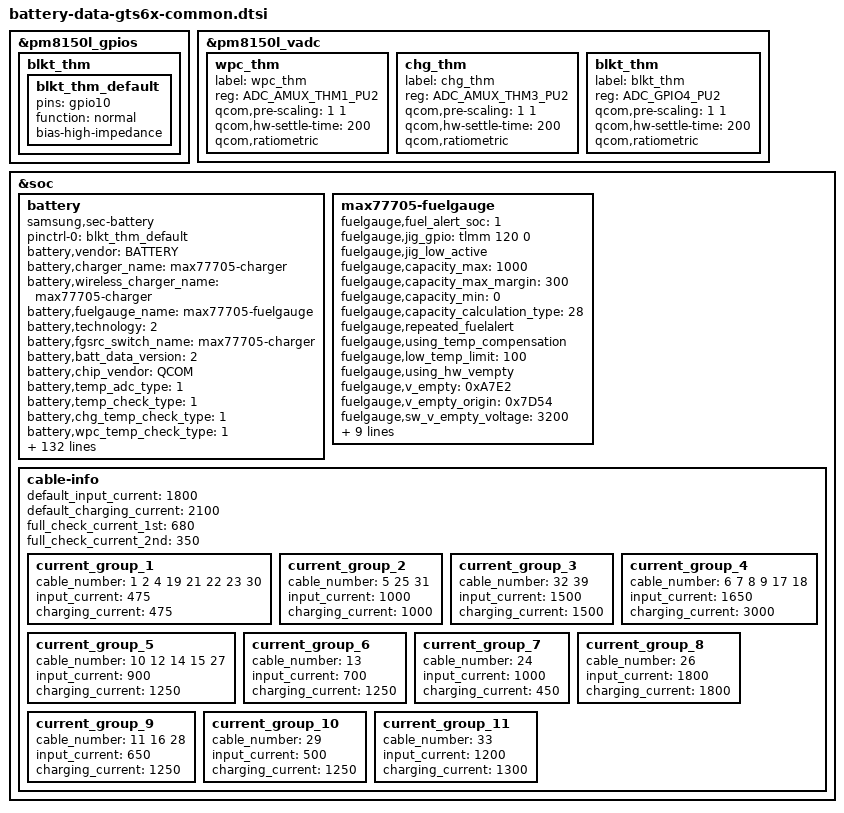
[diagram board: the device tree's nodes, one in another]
/* Copyright (c) 2014, The Linux Foundation. All rights reserved.
 *
 * This program is free software; you can redistribute it and/or modify
 * it under the terms of the GNU General Public License version 2 and
 * only version 2 as published by the Free Software Foundation.
 *
 * This program is distributed in the hope that it will be useful,
 * but WITHOUT ANY WARRANTY; without even the implied warranty of
 * MERCHANTABILITY or FITNESS FOR A PARTICULAR PURPOSE.  See the
 * GNU General Public License for more details.
 */

&pm8150l_gpios {
	blkt_thm { /* GPIO_10 */
		blkt_thm_default: blkt_thm_default {
			pins = "gpio10";
			function = "normal";
			bias-high-impedance;
		};
	};
};

&pm8150l_vadc {
	wpc_thm { /* AMUX_1 */
		label = "wpc_thm";
		reg = <ADC_AMUX_THM1_PU2>;
		qcom,pre-scaling = <1 1>;
		qcom,hw-settle-time = <200>;
		qcom,ratiometric;
	};
	chg_thm { /* AMUX_3 */
		label = "chg_thm";
		reg = <ADC_AMUX_THM3_PU2>;
		qcom,pre-scaling = <1 1>;
		qcom,hw-settle-time = <200>;
		qcom,ratiometric;
	};
	blkt_thm { /* GPIO_10 */
		label = "blkt_thm";
		reg = <ADC_GPIO4_PU2>;
		qcom,pre-scaling = <1 1>;
		qcom,hw-settle-time = <200>;
		qcom,ratiometric;
	};
};

&soc {
	battery {
		status = "okay";
		compatible = "samsung,sec-battery";
		pinctrl-names = "default";
		pinctrl-0 = <&blkt_thm_default>;
		battery,vendor = "BATTERY";
		battery,charger_name = "max77705-charger";
		battery,wireless_charger_name = "max77705-charger";
		battery,fuelgauge_name = "max77705-fuelgauge";
		battery,technology = <2>; /* POWER_SUPPLY_TECHNOLOGY_LION */
		battery,fgsrc_switch_name = "max77705-charger"; /* Fuelgauge voltage source */

		battery,batt_data_version = <2>;

		battery,chip_vendor = "QCOM";
		battery,temp_adc_type = <1>; /* SEC_BATTERY_ADC_TYPE_AP */

		battery,temp_check_type = <1>; /* SEC_BATTERY_TEMP_CHECK_ADC */
		battery,chg_temp_check_type = <1>;
		battery,wpc_temp_check_type = <1>;  // 0 /* SEC_BATTERY_TEMP_CHECK_NONE */
		battery,blkt_temp_check_type = <1>;

		battery,thermal_source = <2>; /* SEC_BATTERY_THERMAL_SOURCE_ADC */
		battery,chg_thermal_source = <2>; /* SEC_BATTERY_THERMAL_SOURCE_ADC */
		battery,wpc_thermal_source = <2>; /* SEC_BATTERY_THERMAL_SOURCE_ADC */
		battery,blkt_thermal_source = <2>; /* SEC_BATTERY_THERMAL_SOURCE_ADC */

		battery,polling_time = <10 30 30 30 3600>;

		battery,temp_table_adc = <123657 151426 179195 211497 245407
						288105 326527 385524 450849 530953
						616406 708974 815008 922577 1031321
						1142913 1245969 1348146 1442228 1527594
						1602039 1667278 1716298>;
		battery,temp_table_data = <900 850 800 750 700
						650 600 550 500 450
						400 350 300 250 200
						150 100 50 0 (-50)
						(-100) (-150) (-200)>;

		battery,chg_temp_table_adc = <130989 157146 183303 215909 251412
						293432 331090 389582 455420 534760
						620695 712780 818114 924062 1032453
						1143316 1248384 1350302 1442444 1526988
						1601267 1666082 1715606>;
		battery,chg_temp_table_data = <900 850 800 750 700
						650 600 550 500 450
						400 350 300 250 200
						150 100 50 0 (-50)
						(-100) (-150) (-200)>;

		battery,wpc_temp_table_adc = <123657 151426 179195 211497 245407
						288105 326527 385524 450849 530953
						616406 708974 815008 922577 1031321
						1142913 1245969 1348146 1442228 1527594
						1602039 1667278 1716298>;
		battery,wpc_temp_table_data = <900 850 800 750 700
						650 600 550 500 450
						400 350 300 250 200
						150 100 50 0 (-50)
						(-100) (-150) (-200)>;

		battery,blkt_temp_table_adc = <128134 154443 180752 213105 248464
						290073 328113 386677 452529 532028
						618381 711050 817149 923853 1033044
						1144355 1250518 1352292 1444679 1529692
						1603762 1668230 1717624>;
		battery,blkt_temp_table_data = <900 850 800 750 700
						650 600 550 500 450
						400 350 300 250 200
						150 100 50 0 (-50)
						(-100) (-150) (-200)>;

		battery,adc_check_count = <5>;

		battery,cable_check_type = <4>; /* SEC_BATTERY_CABLE_CHECK_PSY */
		battery,cable_source_type = <1>; /* SEC_BATTERY_CABLE_SOURCE_EXTERNAL */
		battery,polling_type = <1>; /* SEC_BATTERY_MONITOR_ALARM */
		battery,monitor_initial_count = <0>;

		battery,battery_check_type = <0>; /* SEC_BATTERY_CHECK_NONE */
		battery,check_count = <0>;
		battery,check_adc_max = <1440>;
		battery,check_adc_min = <0>;

		battery,ovp_uvlo_check_type = <3>; /* SEC_BATTERY_OVP_UVLO_CHGPOLLING */

		battery,temp_check_count = <1>;
		battery,temp_highlimit_threshold_event = <800>;
		battery,temp_highlimit_recovery_event = <780>;
		battery,temp_high_threshold_event = <500>;
		battery,temp_high_recovery_event = <450>;
		battery,temp_low_threshold_event = <0>;
		battery,temp_low_recovery_event = <50>;
		battery,temp_highlimit_threshold_normal = <800>;
		battery,temp_highlimit_recovery_normal = <780>;
		battery,temp_high_threshold_normal = <500>;
		battery,temp_high_recovery_normal = <450>;
		battery,temp_low_threshold_normal = <0>;
		battery,temp_low_recovery_normal = <50>;
		battery,temp_highlimit_threshold_lpm = <800>;
		battery,temp_highlimit_recovery_lpm = <780>;
		battery,temp_high_threshold_lpm = <500>;
		battery,temp_high_recovery_lpm = <450>;
		battery,temp_low_threshold_lpm = <0>;
		battery,temp_low_recovery_lpm = <50>;
		battery,full_check_type = <2>; /* SEC_BATTERY_FULLCHARGED_FG_CURRENT */
		battery,full_check_type_2nd = <2>; /* SEC_BATTERY_FULLCHARGED_FG_CURRENT */
		battery,full_check_count = <1>;
		battery,chg_gpio_full_check = <0>;
		battery,chg_polarity_full_check = <1>;

		battery,chg_high_temp = <800>;
		battery,chg_high_temp_recovery = <770>;
		battery,chg_input_limit_current = <1000>;
		battery,chg_charging_limit_current = <1500>;

		battery,store_mode_afc_input_current = <700>;

		battery,sleep_mode_limit_current = <500>;

		battery,mix_high_temp = <410>;
		battery,mix_high_chg_temp = <595>;
		battery,mix_high_temp_recovery = <380>;

		/* SEC_BATTERY_FULL_CONDITION_NOTIMEFULL | SEC_BATTERY_FULL_CONDITION_VCELL */
		battery,full_condition_type = <9>;
		battery,full_condition_soc = <93>;
		battery,full_condition_vcell = <4250>;

		battery,recharge_check_count = <1>;
		battery,recharge_condition_type = <4>; /* SEC_BATTERY_RECHARGE_CONDITION_VCELL */
		battery,recharge_condition_soc = <98>;
		battery,recharge_condition_vcell = <4280>;

		battery,charging_total_time = <14400>;
		battery,hv_charging_total_time = <10800>;
		battery,normal_charging_total_time = <18000>;
		battery,usb_charging_total_time = <36000>;
		battery,recharging_total_time = <5400>;
		battery,charging_reset_time = <0>;

		battery,chg_float_voltage = <4350>;
		battery,chg_ocp_current = <5600>;

		battery,pre_afc_work_delay = <2000>;
		battery,pre_wc_afc_work_delay = <4000>;
		battery,pre_afc_input_current = <500>;
		battery,pre_wc_afc_input_current = <500>;
		battery,prepare_ta_delay = <0>; /* msec */

		battery,swelling_high_temp_block = <410>;
		battery,swelling_high_temp_recov = <390>;
		battery,swelling_low_temp_block_1st = <150>;
		battery,swelling_low_temp_recov_1st = <200>;
		battery,swelling_low_temp_block_2nd = <50>;
		battery,swelling_low_temp_recov_2nd = <100>;
		battery,swelling_low_temp_current = <1200>;
		battery,swelling_low_temp_current_2nd = <1200>;
		battery,swelling_low_temp_topoff = <350>;
		battery,swelling_high_temp_current = <1800>;
		battery,swelling_high_temp_topoff = <350>;

		battery,swelling_drop_float_voltage = <4150>;
		battery,swelling_high_rechg_voltage = <4000>;
		battery,swelling_low_rechg_thr = <150>;

		battery,swelling_drop_float_voltage_lowtemp;
		battery,swelling_low_rechg_voltage = <4000>;

		battery,siop_input_limit_current = <1200>;
		battery,siop_charging_limit_current = <1000>;
		battery,siop_hv_input_limit_current = <700>;
		battery,siop_hv_input_limit_current_2nd = <550>;
		battery,siop_hv_charging_limit_current = <1000>;

		battery,ttf_hv_charge_current = <2650>;
		battery,ttf_pogo_charge_current = <1170>;

		battery,rp_current_rp1 = <475>;
		battery,rp_current_rp2 = <1400>;
		battery,rp_current_rp3 = <3000>;
		battery,rp_current_rdu_rp3 = <2100>;
		battery,rp_current_abnormal_rp3 = <1800>;

		battery,pd_charging_charge_power = <15000>;
		battery,max_charging_current = <3000>;

		/* cycle, chg_float_voltage, recharge_condition_vcell, full_condition_vcell, full_condition_soc */
		battery,age_data = <0 4350 4280 4250 93
				300 4330 4260 4230 92
				400 4310 4240 4210 91
				700 4290 4220 4190 90
				1000 4240 4170 4140 89>;

		battery,max_input_voltage = <9000>; /* mV */
		battery,max_input_current = <3000>;  /* mA */

		battery,enable_sysovlo_irq;

		battery,standard_curr = <3000>;
		battery,expired_time = <15000>;
		battery,recharging_expired_time = <5400>;

		battery,battery_full_capacity = <7040>;
		battery,cisd_max_voltage_thr = <4400>; /* batttery ovp dettection voltage */
		battery,cisd_alg_index = <8>;
		battery,ignore_cisd_index = <0 0>;
		battery,ignore_cisd_index_d = <0 120>; /* Do not use AFC_FAIL_PER_DAY to DROP_VALUE_PER_DAY */ 

		io-channels = <&pm8150l_vadc ADC_AMUX_THM1_PU2>, <&pm8150l_vadc ADC_AMUX_THM3_PU2>, <&pm8150l_vadc ADC_AMUX_THM1_PU2>, <&pm8150l_vadc ADC_GPIO4_PU2>;
		io-channel-names = "adc-temp", "adc-chg-temp", "adc-wpc-temp", "adc-blkt-temp";
	};

	max77705-fuelgauge {
		/* for 7040mAh battery */
		status = "okay";
		fuelgauge,fuel_alert_soc = <1>;
		fuelgauge,jig_gpio = <&tlmm 120 0>; /* IFC_SENSE_INT_AP */
		fuelgauge,jig_low_active;
		fuelgauge,capacity_max = <1000>;
		fuelgauge,capacity_max_margin = <300>;
		fuelgauge,capacity_min = <0>;
		fuelgauge,capacity_calculation_type = <28>;
		fuelgauge,repeated_fuelalert;
		fuelgauge,using_temp_compensation;
		fuelgauge,low_temp_limit = <100>;
		fuelgauge,using_hw_vempty;
		fuelgauge,v_empty = <0xA7E2>; /* Empty: 3350mV, Recover: 3480mV */
		fuelgauge,v_empty_origin = <0x7D54>; /* Empty: 2500mV, Recover: 3360mV */
		fuelgauge,sw_v_empty_voltage = <3200>;
		fuelgauge,sw_v_empty_voltage_cisd = <3100>;
		fuelgauge,sw_v_empty_recover_voltage = <3480>;
		fuelgauge,fg_resistor = <5>;
		fuelgauge,capacity = <0x0a44>;
		fuelgauge,discharge_temp_threshold = <600>;
		fuelgauge,discharge_volt_threshold = <4200>;
		fuelgauge,ttf_capacity = <6050>;
		fuelgauge,cv_data = <
			3011	860	1740
			2984	870	1672
			2815	880	1582
			2704	890	1514
			2545	900	1427
			2377	910	1332
			2232	920	1224
			2051	930	1116
			1905	940	1002
			1720	950	842
			1541	960	711
			1397	970	563
			1262	980	383
			1102	990	173
			680	1000	0
		>;
	};

/* sec_battery_cable
 *   0	UNKNOWN,
 *   1	NONE,
 *   2	PREPARE_TA,
 *   3	TA,
 *   4	USB,
 *   5	USB_CDP,
 *   6	9V_TA,
 *   7	9V_ERR,
 *   8	9V_UNKNOWN,
 *   9	12V_TA,
 *  10	WIRELESS,
 *  11	HV_WIRELESS,
 *  12	PMA_WIRELESS,
 *  13	WIRELESS_PACK,
 *  14	CABLE_WIRELESS_HV_PACK,
 *  15	WIRELESS_STAND,
 *  16	WIRELESS_HV_STAND,
 *  17	QC20,
 *  18	QC30,
 *  19	PDIC,
 *  20	UARTOFF,
 *  21	OTG,
 *  22	LAN_HUB,
 *  23	POWER_SHARING,
 *  24	HMT_CONNECTED,
 *  25	HMT_CHARGE,
 *  26	HV_TA_CHG_LIMIT,
 *  27	WIRELESS_VEHICLE,
 *  28	WIRELESS_HV_VEHICLE,
 *  29	PREPARE_WIRELESS_HV,
 *  30  TIMEOUT,
 *  31  SMART_OTG,
 *  32  SMART_NOTG,
 *  33  WIRELESS_TX,
 *  34	HV_WIRELESS_20,
 *  35	HV_WIRELESS_20_LIMIT,
 *  36	WIRELESS_FAKE,
 *  37  PREPARE_WIRELESS_20,
 *  38	CABLE_PDIC_APDO,
 *  39	CABLE_POGO,
 *  40	CABLE_MAX,
 */
	cable-info {
		default_input_current = <1800>;
		default_charging_current = <2100>;
		full_check_current_1st = <680>;
		full_check_current_2nd = <350>;

		current_group_1 {
			cable_number = <1 2 4 19 21 22 23 30>;
			input_current = <475>;
			charging_current = <475>;
		};
		current_group_2 {
			cable_number = <5 25 31>;
			input_current = <1000>;
			charging_current = <1000>;
		};
		current_group_3 {
			cable_number = <32 39>;
			input_current = <1500>;
			charging_current = <1500>;
		};
		current_group_4 {
			cable_number = <6 7 8 9 17 18>;
			input_current = <1650>;
			charging_current = <3000>;
		};
		current_group_5 {
			cable_number = <10 12 14 15 27>;
			input_current = <900>;
			charging_current = <1250>;
		};
		current_group_6 {
			cable_number = <13>;
			input_current = <700>;
			charging_current = <1250>;
		};
		current_group_7 {
			cable_number = <24>;
			input_current = <1000>;
			charging_current = <450>;
		};
		current_group_8 {
			cable_number = <26>;
			input_current = <1800>;
			charging_current = <1800>;
		};
		current_group_9 {
			cable_number = <11 16 28>;
			input_current = <650>;
			charging_current = <1250>;
		};
		current_group_10 {
			cable_number = <29>;
			input_current = <500>;
			charging_current = <1250>;
		};
		current_group_11 {
			cable_number = <33>;
			input_current = <1200>;
			charging_current = <1300>;
		};
	};
};
